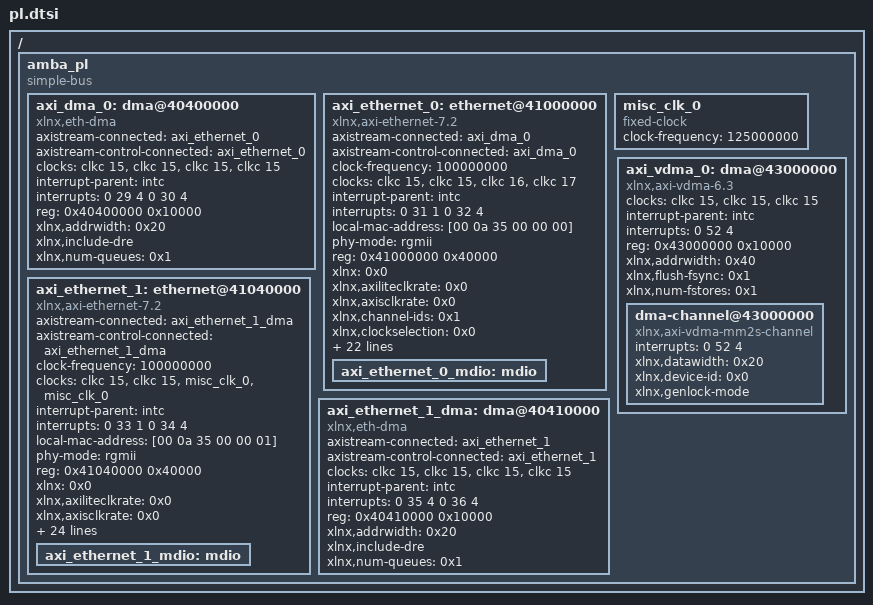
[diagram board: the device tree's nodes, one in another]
/*
 * CAUTION: This file is automatically generated by Xilinx.
 * Version: XSCT 2021.1
 * Today is: Thu May 29 18:24:14 2025
 */


/ {
	amba_pl: amba_pl {
		#address-cells = <1>;
		#size-cells = <1>;
		compatible = "simple-bus";
		ranges ;
		axi_dma_0: dma@40400000 {
			#dma-cells = <1>;
			axistream-connected = <&axi_ethernet_0>;
			axistream-control-connected = <&axi_ethernet_0>;
			clock-names = "s_axi_lite_aclk", "m_axi_sg_aclk", "m_axi_mm2s_aclk", "m_axi_s2mm_aclk";
			clocks = <&clkc 15>, <&clkc 15>, <&clkc 15>, <&clkc 15>;
			compatible = "xlnx,eth-dma";
			interrupt-names = "mm2s_introut", "s2mm_introut";
			interrupt-parent = <&intc>;
			interrupts = <0 29 4 0 30 4>;
			reg = <0x40400000 0x10000>;
			xlnx,addrwidth = /bits/ 8 <0x20>;
			xlnx,include-dre ;
			xlnx,num-queues = /bits/ 16 <0x1>;
		};
		axi_ethernet_0: ethernet@41000000 {
			axistream-connected = <&axi_dma_0>;
			axistream-control-connected = <&axi_dma_0>;
			clock-frequency = <100000000>;
			clock-names = "s_axi_lite_clk", "axis_clk", "gtx_clk", "ref_clk";
			clocks = <&clkc 15>, <&clkc 15>, <&clkc 16>, <&clkc 17>;
			compatible = "xlnx,axi-ethernet-7.2", "xlnx,axi-ethernet-1.00.a";
			device_type = "network";
			interrupt-names = "mac_irq", "interrupt";
			interrupt-parent = <&intc>;
			interrupts = <0 31 1 0 32 4>;
			local-mac-address = [00 0a 35 00 00 00];
			phy-mode = "rgmii";
			reg = <0x41000000 0x40000>;
			xlnx = <0x0>;
			xlnx,axiliteclkrate = <0x0>;
			xlnx,axisclkrate = <0x0>;
			xlnx,channel-ids = <0x1>;
			xlnx,clockselection = <0x0>;
			xlnx,enableasyncsgmii = <0x0>;
			xlnx,gt-type = <0x0>;
			xlnx,gtinex = <0x0>;
			xlnx,gtlocation = <0x0>;
			xlnx,gtrefclksrc = <0x0>;
			xlnx,include-dre ;
			xlnx,instantiatebitslice0 = <0x0>;
			xlnx,num-queues = /bits/ 16 <0x1>;
			xlnx,phy-type = <0x3>;
			xlnx,phyaddr = <0x1>;
			xlnx,phyrst-board-interface-dummy-port = <0x0>;
			xlnx,rable = <0x0>;
			xlnx,rxcsum = <0x0>;
			xlnx,rxlane0-placement = <0x0>;
			xlnx,rxlane1-placement = <0x0>;
			xlnx,rxmem = <0x1000>;
			xlnx,rxnibblebitslice0used = <0x0>;
			xlnx,tx-in-upper-nibble = <0x1>;
			xlnx,txcsum = <0x0>;
			xlnx,txlane0-placement = <0x0>;
			xlnx,txlane1-placement = <0x0>;
			xlnx,versal-gt-board-flow = <0x0>;
			axi_ethernet_0_mdio: mdio {
				#address-cells = <1>;
				#size-cells = <0>;
			};
		};
		axi_ethernet_1: ethernet@41040000 {
			axistream-connected = <&axi_ethernet_1_dma>;
			axistream-control-connected = <&axi_ethernet_1_dma>;
			clock-frequency = <100000000>;
			clock-names = "s_axi_lite_clk", "axis_clk", "gtx_clk", "gtx_clk90";
			clocks = <&clkc 15>, <&clkc 15>, <&misc_clk_0>, <&misc_clk_0>;
			compatible = "xlnx,axi-ethernet-7.2", "xlnx,axi-ethernet-1.00.a";
			device_type = "network";
			interrupt-names = "mac_irq", "interrupt";
			interrupt-parent = <&intc>;
			interrupts = <0 33 1 0 34 4>;
			local-mac-address = [00 0a 35 00 00 01];
			phy-mode = "rgmii";
			reg = <0x41040000 0x40000>;
			xlnx = <0x0>;
			xlnx,axiliteclkrate = <0x0>;
			xlnx,axisclkrate = <0x0>;
			xlnx,channel-ids = <0x1>;
			xlnx,clockselection = <0x0>;
			xlnx,enableasyncsgmii = <0x0>;
			xlnx,gt-type = <0x0>;
			xlnx,gtinex = <0x0>;
			xlnx,gtlocation = <0x0>;
			xlnx,gtrefclksrc = <0x0>;
			xlnx,include-dre ;
			xlnx,instantiatebitslice0 = <0x0>;
			xlnx,num-queues = /bits/ 16 <0x1>;
			xlnx,phy-type = <0x3>;
			xlnx,phyaddr = <0x1>;
			xlnx,phyrst-board-interface-dummy-port = <0x0>;
			xlnx,rable = <0x0>;
			xlnx,rxcsum = <0x0>;
			xlnx,rxlane0-placement = <0x0>;
			xlnx,rxlane1-placement = <0x0>;
			xlnx,rxmem = <0x1000>;
			xlnx,rxnibblebitslice0used = <0x0>;
			xlnx,tx-in-upper-nibble = <0x1>;
			xlnx,txcsum = <0x0>;
			xlnx,txlane0-placement = <0x0>;
			xlnx,txlane1-placement = <0x0>;
			xlnx,versal-gt-board-flow = <0x0>;
			axi_ethernet_1_mdio: mdio {
				#address-cells = <1>;
				#size-cells = <0>;
			};
		};
		misc_clk_0: misc_clk_0 {
			#clock-cells = <0>;
			clock-frequency = <125000000>;
			compatible = "fixed-clock";
		};
		axi_ethernet_1_dma: dma@40410000 {
			#dma-cells = <1>;
			axistream-connected = <&axi_ethernet_1>;
			axistream-control-connected = <&axi_ethernet_1>;
			clock-names = "s_axi_lite_aclk", "m_axi_sg_aclk", "m_axi_mm2s_aclk", "m_axi_s2mm_aclk";
			clocks = <&clkc 15>, <&clkc 15>, <&clkc 15>, <&clkc 15>;
			compatible = "xlnx,eth-dma";
			interrupt-names = "mm2s_introut", "s2mm_introut";
			interrupt-parent = <&intc>;
			interrupts = <0 35 4 0 36 4>;
			reg = <0x40410000 0x10000>;
			xlnx,addrwidth = /bits/ 8 <0x20>;
			xlnx,include-dre ;
			xlnx,num-queues = /bits/ 16 <0x1>;
		};
		axi_vdma_0: dma@43000000 {
			#dma-cells = <1>;
			clock-names = "s_axi_lite_aclk", "m_axi_mm2s_aclk", "m_axis_mm2s_aclk";
			clocks = <&clkc 15>, <&clkc 15>, <&clkc 15>;
			compatible = "xlnx,axi-vdma-6.3", "xlnx,axi-vdma-1.00.a";
			interrupt-names = "mm2s_introut";
			interrupt-parent = <&intc>;
			interrupts = <0 52 4>;
			reg = <0x43000000 0x10000>;
			xlnx,addrwidth = <0x40>;
			xlnx,flush-fsync = <0x1>;
			xlnx,num-fstores = <0x1>;
			dma-channel@43000000 {
				compatible = "xlnx,axi-vdma-mm2s-channel";
				interrupts = <0 52 4>;
				xlnx,datawidth = <0x20>;
				xlnx,device-id = <0x0>;
				xlnx,genlock-mode ;
			};
		};
	};
};
